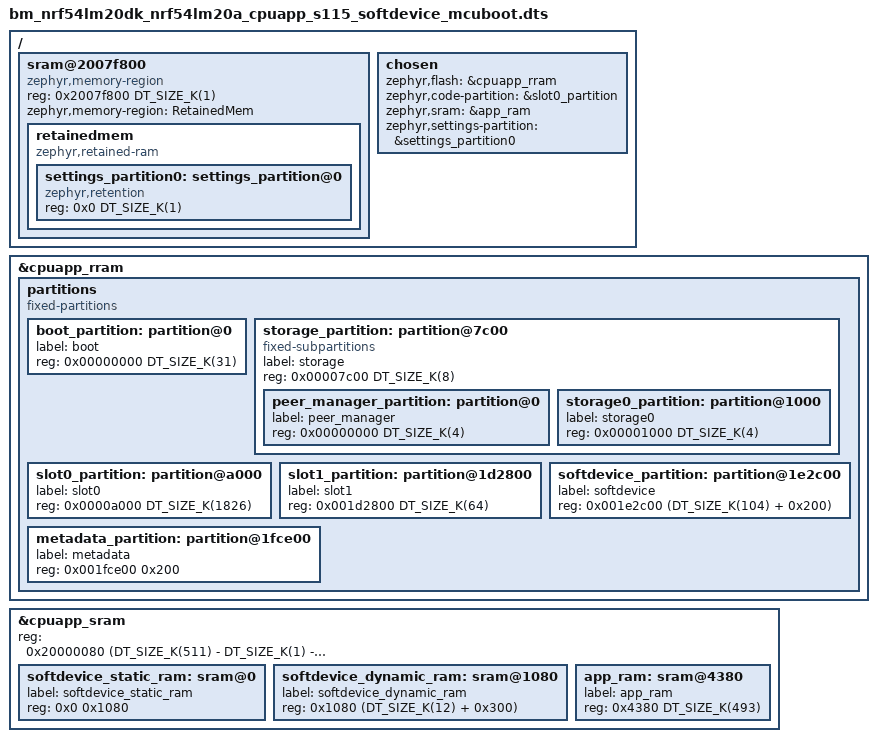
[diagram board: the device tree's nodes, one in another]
/*
 * Copyright (c) 2026 Nordic Semiconductor ASA
 *
 * SPDX-License-Identifier: LicenseRef-Nordic-5-Clause
 */

/dts-v1/;

#include <nordic/nrf54lm20a_cpuapp.dtsi>
#include "bm_nrf54lm20dk_nrf54lm20a_cpuapp_common.dtsi"

/ {
	/* Placed at the end of SRAM, but adjusted to 1kB boundary
	 * (leaving 320 bytes as unused at the end)
	 */
	sram@2007f800 {
		compatible = "zephyr,memory-region", "mmio-sram";
		reg = <0x2007f800 DT_SIZE_K(1)>;
		zephyr,memory-region = "RetainedMem";
		status = "okay";

		retainedmem {
			compatible = "zephyr,retained-ram";
			status = "okay";
			#address-cells = <1>;
			#size-cells = <1>;

			settings_partition0: settings_partition@0 {
				compatible = "zephyr,retention";
				status = "okay";
				reg = <0x0 DT_SIZE_K(1)>;
			};
		};
	};

	chosen {
		zephyr,flash = &cpuapp_rram;
		zephyr,code-partition = &slot0_partition;
		zephyr,sram = &app_ram;
		zephyr,settings-partition = &settings_partition0;
	};
};

&cpuapp_rram {
	status = "okay";

	partitions {
		compatible = "fixed-partitions";
		#address-cells = <1>;
		#size-cells = <1>;

		boot_partition: partition@0 {
			label = "boot";
			reg = <0x00000000 DT_SIZE_K(31)>;
		};

		storage_partition: partition@7c00 {
			compatible = "fixed-subpartitions";
			label = "storage";
			reg = <0x00007c00 DT_SIZE_K(8)>;
			ranges = <0x0 0x7c00 DT_SIZE_K(8)>;
			#address-cells = <1>;
			#size-cells = <1>;

			peer_manager_partition: partition@0 {
				label = "peer_manager";
				reg = <0x00000000 DT_SIZE_K(4)>;
			};

			storage0_partition: partition@1000 {
				label = "storage0";
				reg = <0x00001000 DT_SIZE_K(4)>;
			};
		};

		/* Area from 0x9c00 to 0xa000 is unused due to alignment */

		slot0_partition: partition@a000 {
			label = "slot0";
			reg = <0x0000a000 DT_SIZE_K(1826)>;
		};

		slot1_partition: partition@1d2800 {
			label = "slot1";
			reg = <0x001d2800 DT_SIZE_K(64)>;
		};

		/* Area from 0x1e2800 to 0x1e2c00 is unused due to alignment */

		softdevice_partition: partition@1e2c00 {
			label = "softdevice";
			reg = <0x001e2c00 (DT_SIZE_K(104) + 0x200)>;
		};

		metadata_partition: partition@1fce00 {
			label = "metadata";
			reg = <0x001fce00 0x200>;
		};
	};
};

&cpuapp_sram {
	status = "okay";

	/* Override setting in bm_nrf54lm20dk_nrf54lm20a_cpuapp_common.dtsi
	 * to adjust sram size to not overlap with retainedmem
	 * * (here we ignore the extra 320 bytes at the top end)
	 */
	reg = <0x20000080 (DT_SIZE_K(511) - DT_SIZE_K(1) - 0x80)>;
	ranges = <0x0 0x20000080 (DT_SIZE_K(511) - DT_SIZE_K(1) - 0x80)>;

	softdevice_static_ram: sram@0 {
		label = "softdevice_static_ram";
		reg = <0x0 0x1080>;
	};

	softdevice_dynamic_ram: sram@1080 {
		label = "softdevice_dynamic_ram";
		reg = <0x1080 (DT_SIZE_K(12) + 0x300)>;
	};

	app_ram: sram@4380 {
		label = "app_ram";
		reg = <0x4380 DT_SIZE_K(493)>;
	};
};
